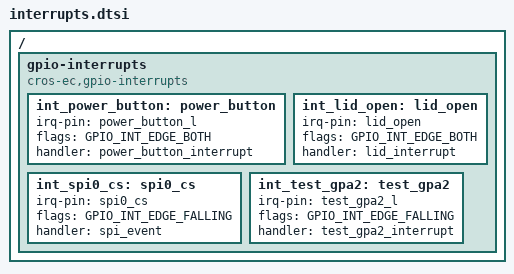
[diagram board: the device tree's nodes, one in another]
/* Copyright 2022 The ChromiumOS Authors
 * Use of this source code is governed by a BSD-style license that can be
 * found in the LICENSE file.
 */

/ {
	gpio-interrupts {
		compatible = "cros-ec,gpio-interrupts";

		int_power_button: power_button {
			irq-pin = <&power_button_l>;
			flags = <GPIO_INT_EDGE_BOTH>;
			handler = "power_button_interrupt";
		};
		int_lid_open: lid_open {
			irq-pin = <&lid_open>;
			flags = <GPIO_INT_EDGE_BOTH>;
			handler = "lid_interrupt";
		};
		int_spi0_cs: spi0_cs {
			irq-pin = <&spi0_cs>;
			flags = <GPIO_INT_EDGE_FALLING>;
			handler = "spi_event";
		};
		int_test_gpa2: test_gpa2 {
			irq-pin = <&test_gpa2_l>;
			flags = <GPIO_INT_EDGE_FALLING>; /* = GPIO_INT_F_FALLING / GPIO_INT_TRIG_LOW */
			handler = "test_gpa2_interrupt";
		};
	};
};
